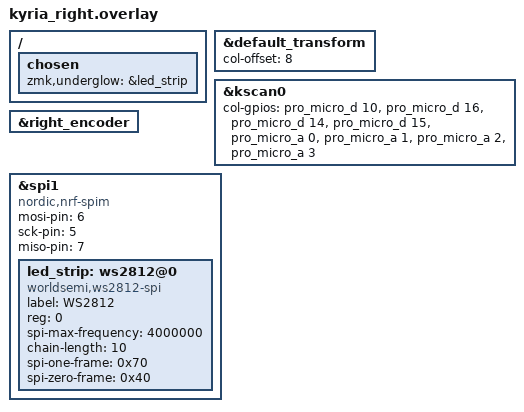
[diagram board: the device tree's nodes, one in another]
/*
 * Copyright (c) 2020 Pete Johanson
 *
 * SPDX-License-Identifier: MIT
 */

#include "kyria.dtsi"

&default_transform {
	col-offset = <8>;
};

&kscan0 {
	col-gpios
		= <&pro_micro_d 10 GPIO_ACTIVE_HIGH>
		, <&pro_micro_d 16 GPIO_ACTIVE_HIGH>
		, <&pro_micro_d 14 GPIO_ACTIVE_HIGH>
		, <&pro_micro_d 15 GPIO_ACTIVE_HIGH>
		, <&pro_micro_a  0 GPIO_ACTIVE_HIGH>
		, <&pro_micro_a  1 GPIO_ACTIVE_HIGH>
		, <&pro_micro_a  2 GPIO_ACTIVE_HIGH>
		, <&pro_micro_a  3 GPIO_ACTIVE_HIGH>
		;
};


&right_encoder {
	status = "okay";
};
&spi1 {
	compatible = "nordic,nrf-spim";
	status = "okay";
	mosi-pin = <6>;
	// Unused pins, needed for SPI definition, but not used by the ws2812 driver itself.
	sck-pin = <5>;
	miso-pin = <7>;

	led_strip: ws2812@0 {
		compatible = "worldsemi,ws2812-spi";
		label = "WS2812";

		/* SPI */
		reg = <0>; /* ignored, but necessary for SPI bindings */
		spi-max-frequency = <4000000>;

		/* WS2812 */
		chain-length = <10>; /* arbitrary; change at will */
		spi-one-frame = <0x70>;
		spi-zero-frame = <0x40>;
	};
};

/ {
	chosen {
		zmk,underglow = &led_strip;
	};
};
